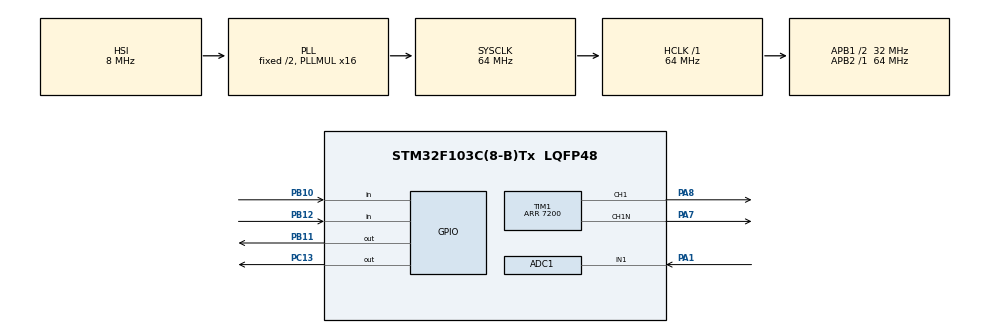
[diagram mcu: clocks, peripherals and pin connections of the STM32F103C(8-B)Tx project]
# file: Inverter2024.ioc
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ADC1.Channel-3\#ChannelRegularConversion=ADC_CHANNEL_1
ADC1.ContinuousConvMode=ENABLE
ADC1.NbrOfConversion=1
ADC1.NbrOfConversionFlag=1
ADC1.Rank-3\#ChannelRegularConversion=1
ADC1.SamplingTime-3\#ChannelRegularConversion=ADC_SAMPLETIME_1CYCLE_5
ADC1.master=1
Mcu.Family=STM32F1
Mcu.Name=STM32F103C(8-B)Tx
Mcu.Package=LQFP48
NVIC.PriorityGroup=NVIC_PRIORITYGROUP_4
NVIC.TIM1_UP_IRQn=true\:0\:0\:false\:false\:true\:true\:true\:true
PA1.Signal=ADCx_IN1
PA7.Mode=PWM Generation1 CH1 CH1N
PA7.Signal=TIM1_CH1N
PA8.Signal=S_TIM1_CH1
PB10.Signal=GPIO_Input
PB11.Signal=GPIO_Output
PB12.Signal=GPIO_Input
PC13-TAMPER-RTC.Signal=GPIO_Output
ProjectManager.HeapSize=0x200
ProjectManager.StackSize=0x400
ProjectManager.TargetToolchain=STM32CubeIDE
RCC.ADCPresc=RCC_ADCPCLK2_DIV6
RCC.AHBFreq_Value=64000000
RCC.APB1CLKDivider=RCC_HCLK_DIV2
RCC.APB1Freq_Value=32000000
RCC.APB1TimFreq_Value=64000000
RCC.APB2Freq_Value=64000000
RCC.APB2TimFreq_Value=64000000
RCC.HCLKFreq_Value=64000000
RCC.PLLMUL=RCC_PLL_MUL16
RCC.SYSCLKFreq_VALUE=64000000
RCC.SYSCLKSource=RCC_SYSCLKSOURCE_PLLCLK
RCC.USBFreq_Value=64000000
SH.ADCx_IN1.0=ADC1_IN1,IN1
SH.S_TIM1_CH1.0=TIM1_CH1,PWM Generation1 CH1 CH1N
TIM1.Channel-PWM\ Generation1\ CH1\ CH1N=TIM_CHANNEL_1
TIM1.DeadTime=255
TIM1.Period=7200
TIM1.Pulse-PWM\ Generation1\ CH1\ CH1N=3600
VP_SYS_VS_ND.Mode=No_Debug
VP_TIM1_VS_ClockSourceINT.Mode=Internal
board=custom

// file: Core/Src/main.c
/* USER CODE BEGIN Header */
/**
  ******************************************************************************
  * @file           : main.c
  * @brief          : Main program body
  ******************************************************************************
  * @attention
  *
  * Copyright (c) 2024 STMicroelectronics.
  * All rights reserved.
  *
  * This software is licensed under terms that can be found in the LICENSE file
  * in the root directory of this software component.
  * If no LICENSE file comes with this software, it is provided AS-IS.
  *
  ******************************************************************************
  */
/* USER CODE END Header */
#include "main.h"

ADC_HandleTypeDef hadc1;

TIM_HandleTypeDef htim1;

void SystemClock_Config(void);
static void MX_GPIO_Init(void);
static void MX_ADC1_Init(void);
static void MX_TIM1_Init(void);

int main(void)
{

  /* MCU Configuration--------------------------------------------------------*/

  /* Reset of all peripherals, Initializes the Flash interface and the Systick. */
  HAL_Init();

  /* Configure the system clock */
  SystemClock_Config();

  /* Initialize all configured peripherals */
  MX_GPIO_Init();
  MX_ADC1_Init();
  MX_TIM1_Init();

  /* Infinite loop */
  /* USER CODE BEGIN WHILE */
  HAL_GPIO_WritePin(GPIOB, GPIO_PIN_11, 1);
  HAL_TIM_PWM_Start_IT(&htim1, TIM_CHANNEL_1);
  HAL_TIMEx_PWMN_Start_IT(&htim1, TIM_CHANNEL_1);
  while (1)
  {
    /* USER CODE END WHILE */

    /* USER CODE BEGIN 3 */
	  HAL_Delay(1000);

	  HAL_GPIO_TogglePin(GPIOC, GPIO_PIN_13);
  }
  /* USER CODE END 3 */
}

void SystemClock_Config(void)
{
  RCC_OscInitTypeDef RCC_OscInitStruct = {0};
  RCC_ClkInitTypeDef RCC_ClkInitStruct = {0};
  RCC_PeriphCLKInitTypeDef PeriphClkInit = {0};

  /** Initializes the RCC Oscillators according to the specified parameters
  * in the RCC_OscInitTypeDef structure.
  */
  RCC_OscInitStruct.OscillatorType = RCC_OSCILLATORTYPE_HSI;
  RCC_OscInitStruct.HSIState = RCC_HSI_ON;
  RCC_OscInitStruct.HSICalibrationValue = RCC_HSICALIBRATION_DEFAULT;
  RCC_OscInitStruct.PLL.PLLState = RCC_PLL_ON;
  RCC_OscInitStruct.PLL.PLLSource = RCC_PLLSOURCE_HSI_DIV2;
  RCC_OscInitStruct.PLL.PLLMUL = RCC_PLL_MUL16;
  if (HAL_RCC_OscConfig(&RCC_OscInitStruct) != HAL_OK)
  {
    Error_Handler();
  }

  /** Initializes the CPU, AHB and APB buses clocks
  */
  RCC_ClkInitStruct.ClockType = RCC_CLOCKTYPE_HCLK|RCC_CLOCKTYPE_SYSCLK
                              |RCC_CLOCKTYPE_PCLK1|RCC_CLOCKTYPE_PCLK2;
  RCC_ClkInitStruct.SYSCLKSource = RCC_SYSCLKSOURCE_PLLCLK;
  RCC_ClkInitStruct.AHBCLKDivider = RCC_SYSCLK_DIV1;
  RCC_ClkInitStruct.APB1CLKDivider = RCC_HCLK_DIV2;
  RCC_ClkInitStruct.APB2CLKDivider = RCC_HCLK_DIV1;

  if (HAL_RCC_ClockConfig(&RCC_ClkInitStruct, FLASH_LATENCY_2) != HAL_OK)
  {
    Error_Handler();
  }
  PeriphClkInit.PeriphClockSelection = RCC_PERIPHCLK_ADC;
  PeriphClkInit.AdcClockSelection = RCC_ADCPCLK2_DIV6;
  if (HAL_RCCEx_PeriphCLKConfig(&PeriphClkInit) != HAL_OK)
  {
    Error_Handler();
  }
}

static void MX_ADC1_Init(void)
{

  ADC_ChannelConfTypeDef sConfig = {0};

  /** Common config
  */
  hadc1.Instance = ADC1;
  hadc1.Init.ScanConvMode = ADC_SCAN_DISABLE;
  hadc1.Init.ContinuousConvMode = ENABLE;
  hadc1.Init.DiscontinuousConvMode = DISABLE;
  hadc1.Init.ExternalTrigConv = ADC_SOFTWARE_START;
  hadc1.Init.DataAlign = ADC_DATAALIGN_RIGHT;
  hadc1.Init.NbrOfConversion = 1;
  if (HAL_ADC_Init(&hadc1) != HAL_OK)
  {
    Error_Handler();
  }

  /** Configure Regular Channel
  */
  sConfig.Channel = ADC_CHANNEL_1;
  sConfig.Rank = ADC_REGULAR_RANK_1;
  sConfig.SamplingTime = ADC_SAMPLETIME_1CYCLE_5;
  if (HAL_ADC_ConfigChannel(&hadc1, &sConfig) != HAL_OK)
  {
    Error_Handler();
  }

}

static void MX_TIM1_Init(void)
{

  TIM_ClockConfigTypeDef sClockSourceConfig = {0};
  TIM_MasterConfigTypeDef sMasterConfig = {0};
  TIM_OC_InitTypeDef sConfigOC = {0};
  TIM_BreakDeadTimeConfigTypeDef sBreakDeadTimeConfig = {0};

  htim1.Instance = TIM1;
  htim1.Init.Prescaler = 0;
  htim1.Init.CounterMode = TIM_COUNTERMODE_UP;
  htim1.Init.Period = 7200;
  htim1.Init.ClockDivision = TIM_CLOCKDIVISION_DIV1;
  htim1.Init.RepetitionCounter = 0;
  htim1.Init.AutoReloadPreload = TIM_AUTORELOAD_PRELOAD_DISABLE;
  if (HAL_TIM_Base_Init(&htim1) != HAL_OK)
  {
    Error_Handler();
  }
  sClockSourceConfig.ClockSource = TIM_CLOCKSOURCE_INTERNAL;
  if (HAL_TIM_ConfigClockSource(&htim1, &sClockSourceConfig) != HAL_OK)
  {
    Error_Handler();
  }
  if (HAL_TIM_PWM_Init(&htim1) != HAL_OK)
  {
    Error_Handler();
  }
  sMasterConfig.MasterOutputTrigger = TIM_TRGO_RESET;
  sMasterConfig.MasterSlaveMode = TIM_MASTERSLAVEMODE_DISABLE;
  if (HAL_TIMEx_MasterConfigSynchronization(&htim1, &sMasterConfig) != HAL_OK)
  {
    Error_Handler();
  }
  sConfigOC.OCMode = TIM_OCMODE_PWM1;
  sConfigOC.Pulse = 3600;
  sConfigOC.OCPolarity = TIM_OCPOLARITY_HIGH;
  sConfigOC.OCNPolarity = TIM_OCNPOLARITY_HIGH;
  sConfigOC.OCFastMode = TIM_OCFAST_DISABLE;
  sConfigOC.OCIdleState = TIM_OCIDLESTATE_RESET;
  sConfigOC.OCNIdleState = TIM_OCNIDLESTATE_RESET;
  if (HAL_TIM_PWM_ConfigChannel(&htim1, &sConfigOC, TIM_CHANNEL_1) != HAL_OK)
  {
    Error_Handler();
  }
  sBreakDeadTimeConfig.OffStateRunMode = TIM_OSSR_DISABLE;
  sBreakDeadTimeConfig.OffStateIDLEMode = TIM_OSSI_DISABLE;
  sBreakDeadTimeConfig.LockLevel = TIM_LOCKLEVEL_OFF;
  sBreakDeadTimeConfig.DeadTime = 255;
  sBreakDeadTimeConfig.BreakState = TIM_BREAK_DISABLE;
  sBreakDeadTimeConfig.BreakPolarity = TIM_BREAKPOLARITY_HIGH;
  sBreakDeadTimeConfig.AutomaticOutput = TIM_AUTOMATICOUTPUT_DISABLE;
  if (HAL_TIMEx_ConfigBreakDeadTime(&htim1, &sBreakDeadTimeConfig) != HAL_OK)
  {
    Error_Handler();
  }
  HAL_TIM_MspPostInit(&htim1);

}

static void MX_GPIO_Init(void)
{
  GPIO_InitTypeDef GPIO_InitStruct = {0};

  /* GPIO Ports Clock Enable */
  __HAL_RCC_GPIOC_CLK_ENABLE();
  __HAL_RCC_GPIOA_CLK_ENABLE();
  __HAL_RCC_GPIOB_CLK_ENABLE();

  /*Configure GPIO pin Output Level */
  HAL_GPIO_WritePin(GPIOC, GPIO_PIN_13, GPIO_PIN_RESET);

  /*Configure GPIO pin Output Level */
  HAL_GPIO_WritePin(GPIOB, GPIO_PIN_11, GPIO_PIN_RESET);

  /*Configure GPIO pin : PC13 */
  GPIO_InitStruct.Pin = GPIO_PIN_13;
  GPIO_InitStruct.Mode = GPIO_MODE_OUTPUT_PP;
  GPIO_InitStruct.Pull = GPIO_NOPULL;
  GPIO_InitStruct.Speed = GPIO_SPEED_FREQ_LOW;
  HAL_GPIO_Init(GPIOC, &GPIO_InitStruct);

  /*Configure GPIO pins : PB10 PB12 */
  GPIO_InitStruct.Pin = GPIO_PIN_10|GPIO_PIN_12;
  GPIO_InitStruct.Mode = GPIO_MODE_INPUT;
  GPIO_InitStruct.Pull = GPIO_NOPULL;
  HAL_GPIO_Init(GPIOB, &GPIO_InitStruct);

  /*Configure GPIO pin : PB11 */
  GPIO_InitStruct.Pin = GPIO_PIN_11;
  GPIO_InitStruct.Mode = GPIO_MODE_OUTPUT_PP;
  GPIO_InitStruct.Pull = GPIO_NOPULL;
  GPIO_InitStruct.Speed = GPIO_SPEED_FREQ_LOW;
  HAL_GPIO_Init(GPIOB, &GPIO_InitStruct);

}

void Error_Handler(void)
{
  __disable_irq();
  while (1)
  {
  }
}
